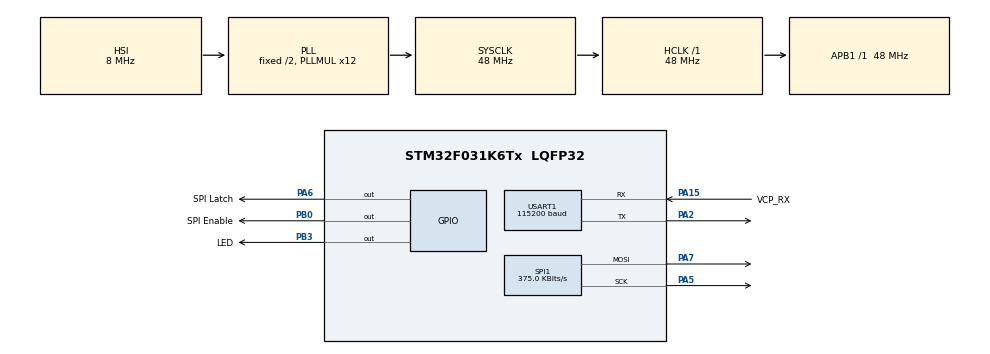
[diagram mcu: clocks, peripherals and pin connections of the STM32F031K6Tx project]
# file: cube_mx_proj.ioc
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Mcu.Family=STM32F0
Mcu.Name=STM32F031K6Tx
Mcu.Package=LQFP32
NVIC.TIM1_BRK_UP_TRG_COM_IRQn=true\:0\:0\:false\:false\:true\:true\:true
NVIC.TIM1_CC_IRQn=true\:0\:0\:false\:false\:true\:true\:true
PA13.GPIO_Label=SWDIO
PA13.Signal=SYS_SWDIO
PA14.GPIO_Label=SWCLK
PA14.Signal=SYS_SWCLK
PA15.GPIO_Label=VCP_RX
PA15.Mode=Asynchronous
PA15.Signal=USART1_RX
PA2.Mode=Asynchronous
PA2.Signal=USART1_TX
PA5.Mode=TX_Only_Simplex_Unidirect_Master
PA5.Signal=SPI1_SCK
PA6.GPIO_Label=SPI Latch
PA6.Signal=GPIO_Output
PA7.Mode=TX_Only_Simplex_Unidirect_Master
PA7.Signal=SPI1_MOSI
PB0.GPIO_Label=SPI Enable
PB0.Signal=GPIO_Output
PB3.GPIO_Label=LED
PB3.Signal=GPIO_Output
PF0-OSC_IN.Signal=RCC_OSC_IN
ProjectManager.HeapSize=0x200
ProjectManager.StackSize=0x400
ProjectManager.TargetToolchain=TrueSTUDIO
RCC.AHBFreq_Value=48000000
RCC.APB1Freq_Value=48000000
RCC.APB1TimFreq_Value=48000000
RCC.HCLKFreq_Value=48000000
RCC.PLLMUL=RCC_PLL_MUL12
RCC.SYSCLKFreq_VALUE=48000000
RCC.SYSCLKSource=RCC_SYSCLKSOURCE_PLLCLK
SPI1.BaudRatePrescaler=SPI_BAUDRATEPRESCALER_128
SPI1.CalculateBaudRate=375.0 KBits/s
SPI1.DataSize=SPI_DATASIZE_8BIT
SPI1.Direction=SPI_DIRECTION_2LINES
SPI1.FirstBit=SPI_FIRSTBIT_LSB
SPI1.Mode=SPI_MODE_MASTER
SPI1.VirtualType=VM_MASTER
TIM1.Period=1249
TIM1.Prescaler=49
USART1.BaudRate=115200
USART1.VirtualMode-Asynchronous=VM_ASYNC
VP_TIM1_VS_ClockSourceINT.Mode=Internal
board=NUCLEO-F031K6

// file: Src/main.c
/* USER CODE BEGIN Header */
/**
  ******************************************************************************
  * @file           : main.c
  * @brief          : Main program body
  ******************************************************************************
  * @attention
  *
  * <h2><center>&copy; Copyright (c) 2019 STMicroelectronics.
  * All rights reserved.</center></h2>
  *
  * This software component is licensed by ST under BSD 3-Clause license,
  * the "License"; You may not use this file except in compliance with the
  * License. You may obtain a copy of the License at:
  *                        opensource.org/licenses/BSD-3-Clause
  *
  ******************************************************************************
  */
/* USER CODE END Header */

#include "main.h"

/* USER CODE BEGIN Includes */
#include "program.h"
/* USER CODE END Includes */

SPI_HandleTypeDef hspi1;

TIM_HandleTypeDef htim1;

UART_HandleTypeDef huart1;

void SystemClock_Config(void);
static void MX_GPIO_Init(void);
static void MX_USART1_UART_Init(void);
static void MX_TIM1_Init(void);
static void MX_SPI1_Init(void);

int main(void)
{

  /* MCU Configuration--------------------------------------------------------*/

  /* Reset of all peripherals, Initializes the Flash interface and the Systick. */
  HAL_Init();

  /* Configure the system clock */
  SystemClock_Config();

  /* Initialize all configured peripherals */
  MX_GPIO_Init();
  MX_USART1_UART_Init();
  MX_TIM1_Init();
  MX_SPI1_Init();
  /* USER CODE BEGIN 2 */

  HAL_TIM_Base_Start_IT(&htim1);
  program_init();

  /* USER CODE END 2 */

  /* Infinite loop */
  while (1)
  {

    /* USER CODE BEGIN 3 */
	mainLoop();
  }
  /* USER CODE END 3 */
}

void SystemClock_Config(void)
{
  RCC_OscInitTypeDef RCC_OscInitStruct = {0};
  RCC_ClkInitTypeDef RCC_ClkInitStruct = {0};
  RCC_PeriphCLKInitTypeDef PeriphClkInit = {0};

  /** Initializes the CPU, AHB and APB busses clocks
  */
  RCC_OscInitStruct.OscillatorType = RCC_OSCILLATORTYPE_HSI;
  RCC_OscInitStruct.HSIState = RCC_HSI_ON;
  RCC_OscInitStruct.HSICalibrationValue = RCC_HSICALIBRATION_DEFAULT;
  RCC_OscInitStruct.PLL.PLLState = RCC_PLL_ON;
  RCC_OscInitStruct.PLL.PLLSource = RCC_PLLSOURCE_HSI;
  RCC_OscInitStruct.PLL.PLLMUL = RCC_PLL_MUL12;
  RCC_OscInitStruct.PLL.PREDIV = RCC_PREDIV_DIV1;
  if (HAL_RCC_OscConfig(&RCC_OscInitStruct) != HAL_OK)
  {
    Error_Handler();
  }
  /** Initializes the CPU, AHB and APB busses clocks
  */
  RCC_ClkInitStruct.ClockType = RCC_CLOCKTYPE_HCLK|RCC_CLOCKTYPE_SYSCLK
                              |RCC_CLOCKTYPE_PCLK1;
  RCC_ClkInitStruct.SYSCLKSource = RCC_SYSCLKSOURCE_PLLCLK;
  RCC_ClkInitStruct.AHBCLKDivider = RCC_SYSCLK_DIV1;
  RCC_ClkInitStruct.APB1CLKDivider = RCC_HCLK_DIV1;

  if (HAL_RCC_ClockConfig(&RCC_ClkInitStruct, FLASH_LATENCY_1) != HAL_OK)
  {
    Error_Handler();
  }
  PeriphClkInit.PeriphClockSelection = RCC_PERIPHCLK_USART1;
  PeriphClkInit.Usart1ClockSelection = RCC_USART1CLKSOURCE_PCLK1;
  if (HAL_RCCEx_PeriphCLKConfig(&PeriphClkInit) != HAL_OK)
  {
    Error_Handler();
  }
}

static void MX_SPI1_Init(void)
{

  /* SPI1 parameter configuration*/
  hspi1.Instance = SPI1;
  hspi1.Init.Mode = SPI_MODE_MASTER;
  hspi1.Init.Direction = SPI_DIRECTION_2LINES;
  hspi1.Init.DataSize = SPI_DATASIZE_8BIT;
  hspi1.Init.CLKPolarity = SPI_POLARITY_LOW;
  hspi1.Init.CLKPhase = SPI_PHASE_1EDGE;
  hspi1.Init.NSS = SPI_NSS_SOFT;
  hspi1.Init.BaudRatePrescaler = SPI_BAUDRATEPRESCALER_128;
  hspi1.Init.FirstBit = SPI_FIRSTBIT_LSB;
  hspi1.Init.TIMode = SPI_TIMODE_DISABLE;
  hspi1.Init.CRCCalculation = SPI_CRCCALCULATION_DISABLE;
  hspi1.Init.CRCPolynomial = 7;
  hspi1.Init.CRCLength = SPI_CRC_LENGTH_DATASIZE;
  hspi1.Init.NSSPMode = SPI_NSS_PULSE_ENABLE;
  if (HAL_SPI_Init(&hspi1) != HAL_OK)
  {
    Error_Handler();
  }

}

static void MX_TIM1_Init(void)
{

  TIM_ClockConfigTypeDef sClockSourceConfig = {0};
  TIM_MasterConfigTypeDef sMasterConfig = {0};

  htim1.Instance = TIM1;
  htim1.Init.Prescaler = 49;
  htim1.Init.CounterMode = TIM_COUNTERMODE_UP;
  htim1.Init.Period = 1249;
  htim1.Init.ClockDivision = TIM_CLOCKDIVISION_DIV1;
  htim1.Init.RepetitionCounter = 0;
  htim1.Init.AutoReloadPreload = TIM_AUTORELOAD_PRELOAD_DISABLE;
  if (HAL_TIM_Base_Init(&htim1) != HAL_OK)
  {
    Error_Handler();
  }
  sClockSourceConfig.ClockSource = TIM_CLOCKSOURCE_INTERNAL;
  if (HAL_TIM_ConfigClockSource(&htim1, &sClockSourceConfig) != HAL_OK)
  {
    Error_Handler();
  }
  sMasterConfig.MasterOutputTrigger = TIM_TRGO_RESET;
  sMasterConfig.MasterSlaveMode = TIM_MASTERSLAVEMODE_DISABLE;
  if (HAL_TIMEx_MasterConfigSynchronization(&htim1, &sMasterConfig) != HAL_OK)
  {
    Error_Handler();
  }

}

static void MX_USART1_UART_Init(void)
{

  huart1.Instance = USART1;
  huart1.Init.BaudRate = 115200;
  huart1.Init.WordLength = UART_WORDLENGTH_8B;
  huart1.Init.StopBits = UART_STOPBITS_1;
  huart1.Init.Parity = UART_PARITY_NONE;
  huart1.Init.Mode = UART_MODE_TX_RX;
  huart1.Init.HwFlowCtl = UART_HWCONTROL_NONE;
  huart1.Init.OverSampling = UART_OVERSAMPLING_16;
  huart1.Init.OneBitSampling = UART_ONE_BIT_SAMPLE_DISABLE;
  huart1.AdvancedInit.AdvFeatureInit = UART_ADVFEATURE_NO_INIT;
  if (HAL_UART_Init(&huart1) != HAL_OK)
  {
    Error_Handler();
  }

}

static void MX_GPIO_Init(void)
{
  GPIO_InitTypeDef GPIO_InitStruct = {0};

  /* GPIO Ports Clock Enable */
  __HAL_RCC_GPIOF_CLK_ENABLE();
  __HAL_RCC_GPIOA_CLK_ENABLE();
  __HAL_RCC_GPIOB_CLK_ENABLE();

  /*Configure GPIO pin Output Level */
  HAL_GPIO_WritePin(SPI_Latch_GPIO_Port, SPI_Latch_Pin, GPIO_PIN_RESET);

  /*Configure GPIO pin Output Level */
  HAL_GPIO_WritePin(GPIOB, SPI_Enable_Pin|LED_Pin, GPIO_PIN_RESET);

  /*Configure GPIO pin : SPI_Latch_Pin */
  GPIO_InitStruct.Pin = SPI_Latch_Pin;
  GPIO_InitStruct.Mode = GPIO_MODE_OUTPUT_PP;
  GPIO_InitStruct.Pull = GPIO_NOPULL;
  GPIO_InitStruct.Speed = GPIO_SPEED_FREQ_LOW;
  HAL_GPIO_Init(SPI_Latch_GPIO_Port, &GPIO_InitStruct);

  /*Configure GPIO pins : SPI_Enable_Pin LED_Pin */
  GPIO_InitStruct.Pin = SPI_Enable_Pin|LED_Pin;
  GPIO_InitStruct.Mode = GPIO_MODE_OUTPUT_PP;
  GPIO_InitStruct.Pull = GPIO_NOPULL;
  GPIO_InitStruct.Speed = GPIO_SPEED_FREQ_LOW;
  HAL_GPIO_Init(GPIOB, &GPIO_InitStruct);

}

/* USER CODE BEGIN 4 */
void HAL_TIM_PeriodElapsedCallback(TIM_HandleTypeDef *htim)
{
	if(htim == &htim1)
	{
		timer_callback_10ms();
	}
}
/* USER CODE END 4 */

void Error_Handler(void)
{
}

/************************ (C) COPYRIGHT STMicroelectronics *****END OF FILE****/
